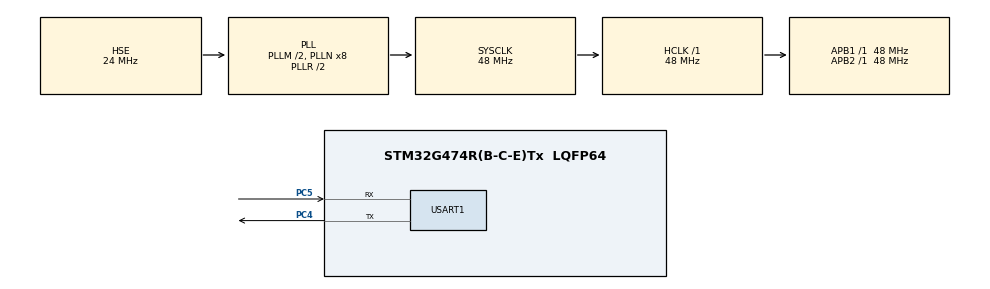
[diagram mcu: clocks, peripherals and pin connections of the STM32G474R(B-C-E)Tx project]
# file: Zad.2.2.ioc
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Mcu.Family=STM32G4
Mcu.Name=STM32G474R(B-C-E)Tx
Mcu.Package=LQFP64
NVIC.PriorityGroup=NVIC_PRIORITYGROUP_4
NVIC.USART1_IRQn=true\:0\:0\:false\:false\:true\:true\:true\:true
PC4.Mode=Asynchronous
PC4.Signal=USART1_TX
PC5.Mode=Asynchronous
PC5.Signal=USART1_RX
PF0-OSC_IN.Mode=HSE-External-Oscillator
PF0-OSC_IN.Signal=RCC_OSC_IN
PF1-OSC_OUT.Mode=HSE-External-Oscillator
PF1-OSC_OUT.Signal=RCC_OSC_OUT
ProjectManager.HeapSize=0x200
ProjectManager.StackSize=0x400
ProjectManager.TargetToolchain=CMake
RCC.ADC12Freq_Value=48000000
RCC.ADC345Freq_Value=48000000
RCC.AHBFreq_Value=48000000
RCC.APB1Freq_Value=48000000
RCC.APB1TimFreq_Value=48000000
RCC.APB2Freq_Value=48000000
RCC.APB2TimFreq_Value=48000000
RCC.CortexFreq_Value=48000000
RCC.EXTERNAL_CLOCK_VALUE=12288000
RCC.HCLKFreq_Value=48000000
RCC.HSE_VALUE=24000000
RCC.HSI48_VALUE=48000000
RCC.HSI_VALUE=16000000
RCC.LSE_VALUE=32768
RCC.PLLM=RCC_PLLM_DIV2
RCC.PLLSourceVirtual=RCC_PLLSOURCE_HSE
RCC.SYSCLKFreq_VALUE=48000000
RCC.SYSCLKSource=RCC_SYSCLKSOURCE_PLLCLK
RCC.USBFreq_Value=48000000
RCC.VCOOutputFreq_Value=96000000
USART1.VirtualMode-Asynchronous=VM_ASYNC
VP_SYS_VS_DBSignals.Mode=DisableDeadBatterySignals
board=custom

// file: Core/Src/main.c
/* USER CODE BEGIN Header */
/**
  ******************************************************************************
  * @file           : main.c
  * @brief          : Main program body
  ******************************************************************************
  * @attention
  *
  * Copyright (c) 2026 STMicroelectronics.
  * All rights reserved.
  *
  * This software is licensed under terms that can be found in the LICENSE file
  * in the root directory of this software component.
  * If no LICENSE file comes with this software, it is provided AS-IS.
  *
  ******************************************************************************
  */
/* USER CODE END Header */
#include "main.h"

/* USER CODE BEGIN Includes */
#include "driver-tlv.h"
#include "msg.h"
#include "packet-handler.h"
/* USER CODE END Includes */

UART_HandleTypeDef huart1;
uint8_t uart_recv;
uint16_t pong_delay = 0;
uint32_t pong_tick = 0;

void SystemClock_Config(void);
static void MX_GPIO_Init(void);
static void MX_USART1_UART_Init(void);

/* USER CODE BEGIN 0 */
void UART_Send_Wrapper(uint8_t *data, uint8_t size) {
	HAL_UART_Transmit(&huart1, data, size, HAL_MAX_DELAY);
}

void HAL_UART_RxCpltCallback(UART_HandleTypeDef *huart) {
	TLV_RecvCallback(uart_recv);

	HAL_UART_Receive_IT(&huart1, &uart_recv, 1);
}
/* USER CODE END 0 */

int main(void)
{

  /* MCU Configuration--------------------------------------------------------*/

  /* Reset of all peripherals, Initializes the Flash interface and the Systick. */
  HAL_Init();

  /* Configure the system clock */
  SystemClock_Config();

  /* Initialize all configured peripherals */
  MX_GPIO_Init();
  MX_USART1_UART_Init();
  /* USER CODE BEGIN 2 */
  TLV_Init(UART_Send_Wrapper);
  HAL_UART_Receive_IT(&huart1, &uart_recv, 1);

  /*
   * Test
   * */
  Send_PING(1000);
  Send_MATH('/', 1024, 16);
  /* USER CODE END 2 */

  /* Infinite loop */
  while (1)
  {
    /* USER CODE BEGIN 3 */
	if(TLV_Available()) {
		packet_t req = TLV_Read();
		Packet_Handler(req);
	}

	if((pong_delay != 0) & (pong_tick == 0)) {
		pong_tick = HAL_GetTick();
	}

	if(((HAL_GetTick() - pong_tick) >= pong_delay) & (pong_delay != 0)) {
		pong_tick = 0;
		pong_delay = 0;
		Send_PONG();
	}
  }
  /* USER CODE END 3 */
}

void SystemClock_Config(void)
{
  RCC_OscInitTypeDef RCC_OscInitStruct = {0};
  RCC_ClkInitTypeDef RCC_ClkInitStruct = {0};

  /** Configure the main internal regulator output voltage
  */
  HAL_PWREx_ControlVoltageScaling(PWR_REGULATOR_VOLTAGE_SCALE1);

  /** Initializes the RCC Oscillators according to the specified parameters
  * in the RCC_OscInitTypeDef structure.
  */
  RCC_OscInitStruct.OscillatorType = RCC_OSCILLATORTYPE_HSE;
  RCC_OscInitStruct.HSEState = RCC_HSE_ON;
  RCC_OscInitStruct.PLL.PLLState = RCC_PLL_ON;
  RCC_OscInitStruct.PLL.PLLSource = RCC_PLLSOURCE_HSE;
  RCC_OscInitStruct.PLL.PLLM = RCC_PLLM_DIV2;
  RCC_OscInitStruct.PLL.PLLN = 8;
  RCC_OscInitStruct.PLL.PLLP = RCC_PLLP_DIV2;
  RCC_OscInitStruct.PLL.PLLQ = RCC_PLLQ_DIV2;
  RCC_OscInitStruct.PLL.PLLR = RCC_PLLR_DIV2;
  if (HAL_RCC_OscConfig(&RCC_OscInitStruct) != HAL_OK)
  {
    Error_Handler();
  }

  /** Initializes the CPU, AHB and APB buses clocks
  */
  RCC_ClkInitStruct.ClockType = RCC_CLOCKTYPE_HCLK|RCC_CLOCKTYPE_SYSCLK
                              |RCC_CLOCKTYPE_PCLK1|RCC_CLOCKTYPE_PCLK2;
  RCC_ClkInitStruct.SYSCLKSource = RCC_SYSCLKSOURCE_PLLCLK;
  RCC_ClkInitStruct.AHBCLKDivider = RCC_SYSCLK_DIV1;
  RCC_ClkInitStruct.APB1CLKDivider = RCC_HCLK_DIV1;
  RCC_ClkInitStruct.APB2CLKDivider = RCC_HCLK_DIV1;

  if (HAL_RCC_ClockConfig(&RCC_ClkInitStruct, FLASH_LATENCY_1) != HAL_OK)
  {
    Error_Handler();
  }
}

static void MX_USART1_UART_Init(void)
{

  huart1.Instance = USART1;
  huart1.Init.BaudRate = 115200;
  huart1.Init.WordLength = UART_WORDLENGTH_8B;
  huart1.Init.StopBits = UART_STOPBITS_1;
  huart1.Init.Parity = UART_PARITY_NONE;
  huart1.Init.Mode = UART_MODE_TX_RX;
  huart1.Init.HwFlowCtl = UART_HWCONTROL_NONE;
  huart1.Init.OverSampling = UART_OVERSAMPLING_16;
  huart1.Init.OneBitSampling = UART_ONE_BIT_SAMPLE_DISABLE;
  huart1.Init.ClockPrescaler = UART_PRESCALER_DIV1;
  huart1.AdvancedInit.AdvFeatureInit = UART_ADVFEATURE_NO_INIT;
  if (HAL_UART_Init(&huart1) != HAL_OK)
  {
    Error_Handler();
  }
  if (HAL_UARTEx_SetTxFifoThreshold(&huart1, UART_TXFIFO_THRESHOLD_1_8) != HAL_OK)
  {
    Error_Handler();
  }
  if (HAL_UARTEx_SetRxFifoThreshold(&huart1, UART_RXFIFO_THRESHOLD_1_8) != HAL_OK)
  {
    Error_Handler();
  }
  if (HAL_UARTEx_DisableFifoMode(&huart1) != HAL_OK)
  {
    Error_Handler();
  }

}

static void MX_GPIO_Init(void)
{

  /* GPIO Ports Clock Enable */
  __HAL_RCC_GPIOF_CLK_ENABLE();
  __HAL_RCC_GPIOC_CLK_ENABLE();

}

void Error_Handler(void)
{
  __disable_irq();
  while (1)
  {
  }
}
